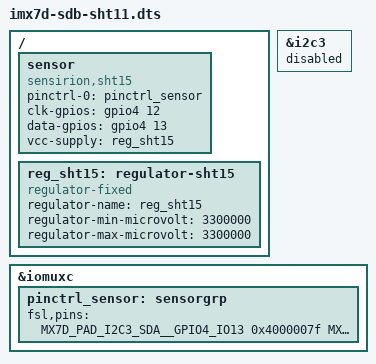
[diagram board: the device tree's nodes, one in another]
// SPDX-License-Identifier: GPL-2.0+ OR MIT
//
// Copyright (C) 2015 Freescale Semiconductor, Inc.

#include "imx7d-sdb.dts"

/ {
	sensor {
		pinctrl-names = "default";
		pinctrl-0 = <&pinctrl_sensor>;
		compatible = "sensirion,sht15";
		clk-gpios = <&gpio4 12 0>;
		data-gpios = <&gpio4 13 0>;
		vcc-supply = <&reg_sht15>;
	};

	reg_sht15: regulator-sht15 {
		compatible = "regulator-fixed";
		regulator-name = "reg_sht15";
		regulator-min-microvolt = <3300000>;
		regulator-max-microvolt = <3300000>;
	};
};

&i2c3 {
	status = "disabled";
};

&iomuxc {
	pinctrl_sensor: sensorgrp {
		fsl,pins = <
			MX7D_PAD_I2C3_SDA__GPIO4_IO13	0x4000007f
			MX7D_PAD_I2C3_SCL__GPIO4_IO12	0x4000007f
		>;
	};
};
